VERSION ""

NS_ :

BS_:

BO_ 1120 NUM_TARGETS: 8 RADAR
  SG_ NUM_TARGETS : 20|5@0+ (1,0) [0|20] ""  NEO

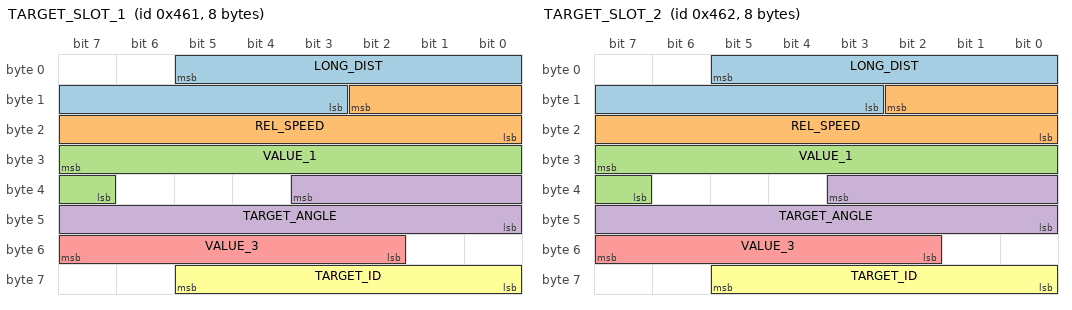
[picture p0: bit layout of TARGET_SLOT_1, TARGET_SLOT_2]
BO_ 1121 TARGET_SLOT_1: 8 RADAR
  SG_ LONG_DIST : 5|11@0+ (0.1,0) [0|200] "m"  NEO
  SG_ REL_SPEED : 10|11@0- (0.15,0) [0|122.85] "m/s"  NEO
  SG_ VALUE_1 : 31|9@0- (1,0) [0|1] ""  NEO
  SG_ TARGET_ANGLE : 35|12@0- (0.15,0) [-30|30] "deg"  NEO
  SG_ VALUE_3 : 55|6@0+ (1,0) [0|1] ""  NEO
  SG_ TARGET_ID : 61|6@0+ (1,0) [0|1] ""  NEO

BO_ 1122 TARGET_SLOT_2: 8 RADAR
  SG_ LONG_DIST : 5|11@0+ (0.1,0) [0|200] "m"  NEO
  SG_ REL_SPEED : 10|11@0- (0.15,0) [0|122.85] "m/s"  NEO
  SG_ VALUE_1 : 31|9@0- (1,0) [0|1] ""  NEO
  SG_ TARGET_ANGLE : 35|12@0- (0.15,0) [-30|30] "deg"  NEO
  SG_ VALUE_3 : 55|6@0+ (1,0) [0|1] ""  NEO
  SG_ TARGET_ID : 61|6@0+ (1,0) [0|1] ""  NEO

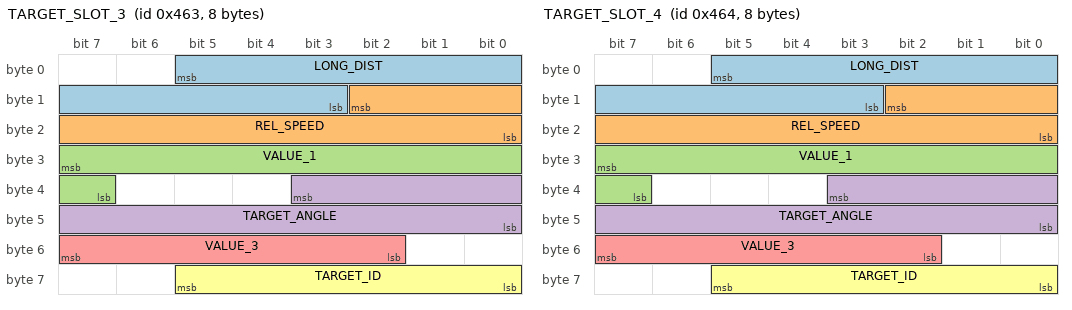
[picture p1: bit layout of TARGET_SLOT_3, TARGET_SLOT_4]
BO_ 1123 TARGET_SLOT_3: 8 RADAR
  SG_ LONG_DIST : 5|11@0+ (0.1,0) [0|200] "m"  NEO
  SG_ REL_SPEED : 10|11@0- (0.15,0) [0|122.85] "m/s"  NEO
  SG_ VALUE_1 : 31|9@0- (1,0) [0|1] ""  NEO
  SG_ TARGET_ANGLE : 35|12@0- (0.15,0) [-30|30] "deg"  NEO
  SG_ VALUE_3 : 55|6@0+ (1,0) [0|1] ""  NEO
  SG_ TARGET_ID : 61|6@0+ (1,0) [0|1] ""  NEO

BO_ 1124 TARGET_SLOT_4: 8 RADAR
  SG_ LONG_DIST : 5|11@0+ (0.1,0) [0|200] "m"  NEO
  SG_ REL_SPEED : 10|11@0- (0.15,0) [0|122.85] "m/s"  NEO
  SG_ VALUE_1 : 31|9@0- (1,0) [0|1] ""  NEO
  SG_ TARGET_ANGLE : 35|12@0- (0.15,0) [-30|30] "deg"  NEO
  SG_ VALUE_3 : 55|6@0+ (1,0) [0|1] ""  NEO
  SG_ TARGET_ID : 61|6@0+ (1,0) [0|1] ""  NEO

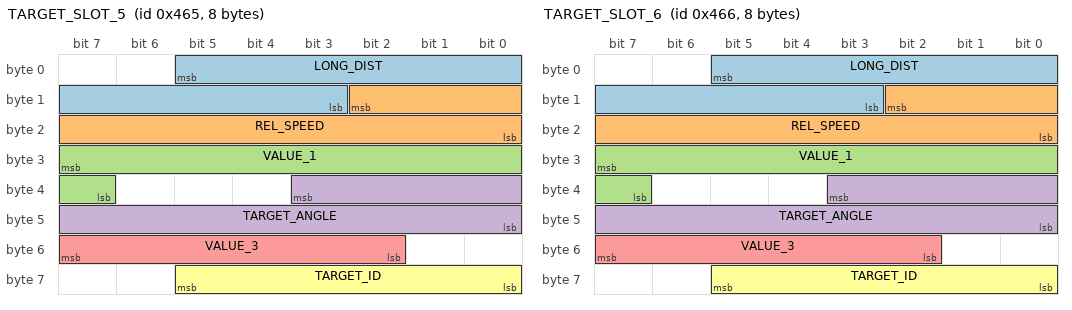
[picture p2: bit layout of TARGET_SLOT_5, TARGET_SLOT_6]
BO_ 1125 TARGET_SLOT_5: 8 RADAR
  SG_ LONG_DIST : 5|11@0+ (0.1,0) [0|200] "m"  NEO
  SG_ REL_SPEED : 10|11@0- (0.15,0) [0|122.85] "m/s"  NEO
  SG_ VALUE_1 : 31|9@0- (1,0) [0|1] ""  NEO
  SG_ TARGET_ANGLE : 35|12@0- (0.15,0) [-30|30] "deg"  NEO
  SG_ VALUE_3 : 55|6@0+ (1,0) [0|1] ""  NEO
  SG_ TARGET_ID : 61|6@0+ (1,0) [0|1] ""  NEO

BO_ 1126 TARGET_SLOT_6: 8 RADAR
  SG_ LONG_DIST : 5|11@0+ (0.1,0) [0|200] "m"  NEO
  SG_ REL_SPEED : 10|11@0- (0.15,0) [0|122.85] "m/s"  NEO
  SG_ VALUE_1 : 31|9@0- (1,0) [0|1] ""  NEO
  SG_ TARGET_ANGLE : 35|12@0- (0.15,0) [-30|30] "deg"  NEO
  SG_ VALUE_3 : 55|6@0+ (1,0) [0|1] ""  NEO
  SG_ TARGET_ID : 61|6@0+ (1,0) [0|1] ""  NEO

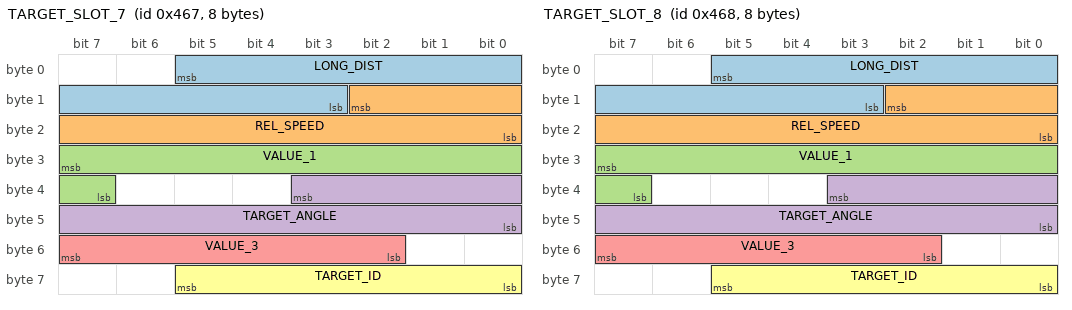
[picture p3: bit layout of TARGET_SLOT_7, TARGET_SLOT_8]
BO_ 1127 TARGET_SLOT_7: 8 RADAR
  SG_ LONG_DIST : 5|11@0+ (0.1,0) [0|200] "m"  NEO
  SG_ REL_SPEED : 10|11@0- (0.15,0) [0|122.85] "m/s"  NEO
  SG_ VALUE_1 : 31|9@0- (1,0) [0|1] ""  NEO
  SG_ TARGET_ANGLE : 35|12@0- (0.15,0) [-30|30] "deg"  NEO
  SG_ VALUE_3 : 55|6@0+ (1,0) [0|1] ""  NEO
  SG_ TARGET_ID : 61|6@0+ (1,0) [0|1] ""  NEO

BO_ 1128 TARGET_SLOT_8: 8 RADAR
  SG_ LONG_DIST : 5|11@0+ (0.1,0) [0|200] "m"  NEO
  SG_ REL_SPEED : 10|11@0- (0.15,0) [0|122.85] "m/s"  NEO
  SG_ VALUE_1 : 31|9@0- (1,0) [0|1] ""  NEO
  SG_ TARGET_ANGLE : 35|12@0- (0.15,0) [-30|30] "deg"  NEO
  SG_ VALUE_3 : 55|6@0+ (1,0) [0|1] ""  NEO
  SG_ TARGET_ID : 61|6@0+ (1,0) [0|1] ""  NEO

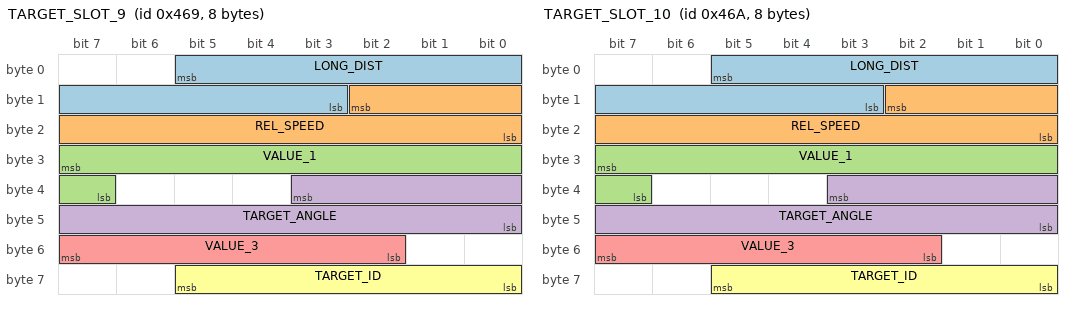
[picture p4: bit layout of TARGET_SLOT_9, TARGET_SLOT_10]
BO_ 1129 TARGET_SLOT_9: 8 RADAR
  SG_ LONG_DIST : 5|11@0+ (0.1,0) [0|200] "m"  NEO
  SG_ REL_SPEED : 10|11@0- (0.15,0) [0|122.85] "m/s"  NEO
  SG_ VALUE_1 : 31|9@0- (1,0) [0|1] ""  NEO
  SG_ TARGET_ANGLE : 35|12@0- (0.15,0) [-30|30] "deg"  NEO
  SG_ VALUE_3 : 55|6@0+ (1,0) [0|1] ""  NEO
  SG_ TARGET_ID : 61|6@0+ (1,0) [0|1] ""  NEO

BO_ 1130 TARGET_SLOT_10: 8 RADAR
  SG_ LONG_DIST : 5|11@0+ (0.1,0) [0|200] "m"  NEO
  SG_ REL_SPEED : 10|11@0- (0.15,0) [0|122.85] "m/s"  NEO
  SG_ VALUE_1 : 31|9@0- (1,0) [0|1] ""  NEO
  SG_ TARGET_ANGLE : 35|12@0- (0.15,0) [-30|30] "deg"  NEO
  SG_ VALUE_3 : 55|6@0+ (1,0) [0|1] ""  NEO
  SG_ TARGET_ID : 61|6@0+ (1,0) [0|1] ""  NEO

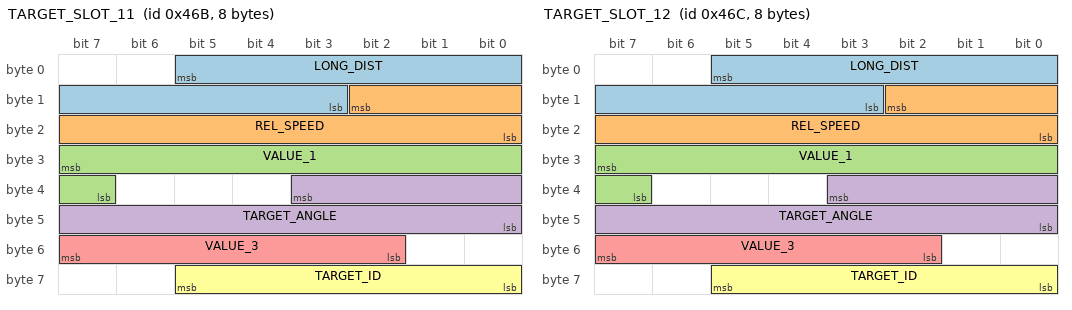
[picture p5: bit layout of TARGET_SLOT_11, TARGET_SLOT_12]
BO_ 1131 TARGET_SLOT_11: 8 RADAR
  SG_ LONG_DIST : 5|11@0+ (0.1,0) [0|200] "m"  NEO
  SG_ REL_SPEED : 10|11@0- (0.15,0) [0|122.85] "m/s"  NEO
  SG_ VALUE_1 : 31|9@0- (1,0) [0|1] ""  NEO
  SG_ TARGET_ANGLE : 35|12@0- (0.15,0) [-30|30] "deg"  NEO
  SG_ VALUE_3 : 55|6@0+ (1,0) [0|1] ""  NEO
  SG_ TARGET_ID : 61|6@0+ (1,0) [0|1] ""  NEO

BO_ 1132 TARGET_SLOT_12: 8 RADAR
  SG_ LONG_DIST : 5|11@0+ (0.1,0) [0|200] "m"  NEO
  SG_ REL_SPEED : 10|11@0- (0.15,0) [0|122.85] "m/s"  NEO
  SG_ VALUE_1 : 31|9@0- (1,0) [0|1] ""  NEO
  SG_ TARGET_ANGLE : 35|12@0- (0.15,0) [-30|30] "deg"  NEO
  SG_ VALUE_3 : 55|6@0+ (1,0) [0|1] ""  NEO
  SG_ TARGET_ID : 61|6@0+ (1,0) [0|1] ""  NEO

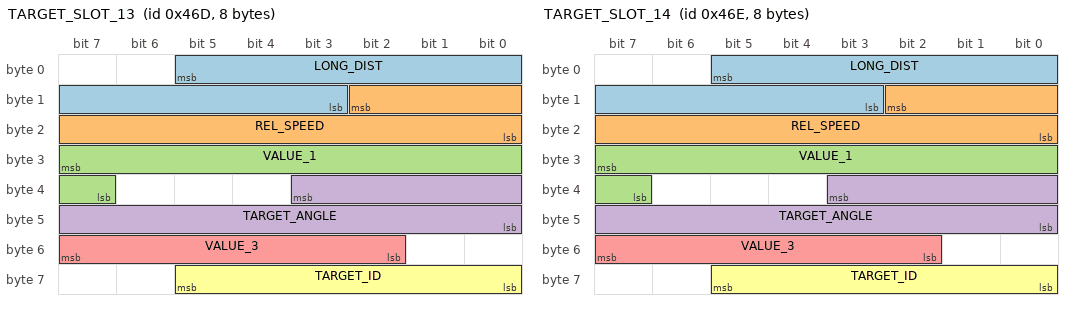
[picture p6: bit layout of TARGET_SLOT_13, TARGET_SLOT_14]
BO_ 1133 TARGET_SLOT_13: 8 RADAR
  SG_ LONG_DIST : 5|11@0+ (0.1,0) [0|200] "m"  NEO
  SG_ REL_SPEED : 10|11@0- (0.15,0) [0|122.85] "m/s"  NEO
  SG_ VALUE_1 : 31|9@0- (1,0) [0|1] ""  NEO
  SG_ TARGET_ANGLE : 35|12@0- (0.15,0) [-30|30] "deg"  NEO
  SG_ VALUE_3 : 55|6@0+ (1,0) [0|1] ""  NEO
  SG_ TARGET_ID : 61|6@0+ (1,0) [0|1] ""  NEO

BO_ 1134 TARGET_SLOT_14: 8 RADAR
  SG_ LONG_DIST : 5|11@0+ (0.1,0) [0|200] "m"  NEO
  SG_ REL_SPEED : 10|11@0- (0.15,0) [0|122.85] "m/s"  NEO
  SG_ VALUE_1 : 31|9@0- (1,0) [0|1] ""  NEO
  SG_ TARGET_ANGLE : 35|12@0- (0.15,0) [-30|30] "deg"  NEO
  SG_ VALUE_3 : 55|6@0+ (1,0) [0|1] ""  NEO
  SG_ TARGET_ID : 61|6@0+ (1,0) [0|1] ""  NEO

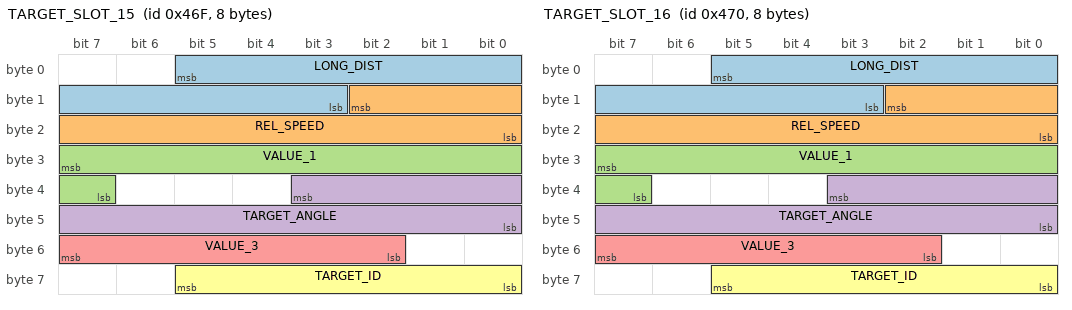
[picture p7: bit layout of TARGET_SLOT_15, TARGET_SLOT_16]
BO_ 1135 TARGET_SLOT_15: 8 RADAR
  SG_ LONG_DIST : 5|11@0+ (0.1,0) [0|200] "m"  NEO
  SG_ REL_SPEED : 10|11@0- (0.15,0) [0|122.85] "m/s"  NEO
  SG_ VALUE_1 : 31|9@0- (1,0) [0|1] ""  NEO
  SG_ TARGET_ANGLE : 35|12@0- (0.15,0) [-30|30] "deg"  NEO
  SG_ VALUE_3 : 55|6@0+ (1,0) [0|1] ""  NEO
  SG_ TARGET_ID : 61|6@0+ (1,0) [0|1] ""  NEO

BO_ 1136 TARGET_SLOT_16: 8 RADAR
  SG_ LONG_DIST : 5|11@0+ (0.1,0) [0|200] "m"  NEO
  SG_ REL_SPEED : 10|11@0- (0.15,0) [0|122.85] "m/s"  NEO
  SG_ VALUE_1 : 31|9@0- (1,0) [0|1] ""  NEO
  SG_ TARGET_ANGLE : 35|12@0- (0.15,0) [-30|30] "deg"  NEO
  SG_ VALUE_3 : 55|6@0+ (1,0) [0|1] ""  NEO
  SG_ TARGET_ID : 61|6@0+ (1,0) [0|1] ""  NEO

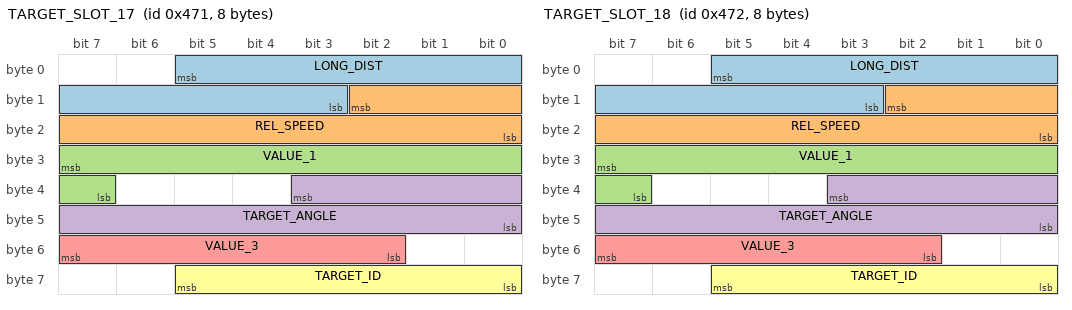
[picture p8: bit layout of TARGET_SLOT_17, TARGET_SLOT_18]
BO_ 1137 TARGET_SLOT_17: 8 RADAR
  SG_ LONG_DIST : 5|11@0+ (0.1,0) [0|200] "m"  NEO
  SG_ REL_SPEED : 10|11@0- (0.15,0) [0|122.85] "m/s"  NEO
  SG_ VALUE_1 : 31|9@0- (1,0) [0|1] ""  NEO
  SG_ TARGET_ANGLE : 35|12@0- (0.15,0) [-30|30] "deg"  NEO
  SG_ VALUE_3 : 55|6@0+ (1,0) [0|1] ""  NEO
  SG_ TARGET_ID : 61|6@0+ (1,0) [0|1] ""  NEO

BO_ 1138 TARGET_SLOT_18: 8 RADAR
  SG_ LONG_DIST : 5|11@0+ (0.1,0) [0|200] "m"  NEO
  SG_ REL_SPEED : 10|11@0- (0.15,0) [0|122.85] "m/s"  NEO
  SG_ VALUE_1 : 31|9@0- (1,0) [0|1] ""  NEO
  SG_ TARGET_ANGLE : 35|12@0- (0.15,0) [-30|30] "deg"  NEO
  SG_ VALUE_3 : 55|6@0+ (1,0) [0|1] ""  NEO
  SG_ TARGET_ID : 61|6@0+ (1,0) [0|1] ""  NEO

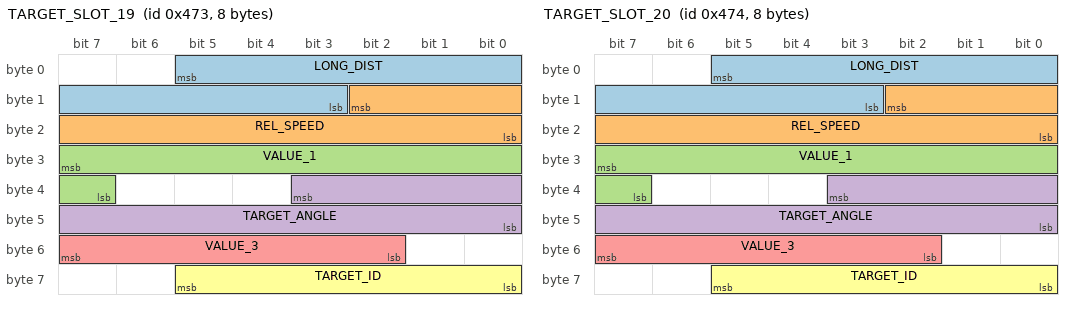
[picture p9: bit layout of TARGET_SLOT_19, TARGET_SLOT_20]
BO_ 1139 TARGET_SLOT_19: 8 RADAR
  SG_ LONG_DIST : 5|11@0+ (0.1,0) [0|200] "m"  NEO
  SG_ REL_SPEED : 10|11@0- (0.15,0) [0|122.85] "m/s"  NEO
  SG_ VALUE_1 : 31|9@0- (1,0) [0|1] ""  NEO
  SG_ TARGET_ANGLE : 35|12@0- (0.15,0) [-30|30] "deg"  NEO
  SG_ VALUE_3 : 55|6@0+ (1,0) [0|1] ""  NEO
  SG_ TARGET_ID : 61|6@0+ (1,0) [0|1] ""  NEO

BO_ 1140 TARGET_SLOT_20: 8 RADAR
  SG_ LONG_DIST : 5|11@0+ (0.1,0) [0|200] "m"  NEO
  SG_ REL_SPEED : 10|11@0- (0.15,0) [0|122.85] "m/s"  NEO
  SG_ VALUE_1 : 31|9@0- (1,0) [0|1] ""  NEO
  SG_ TARGET_ANGLE : 35|12@0- (0.15,0) [-30|30] "deg"  NEO
  SG_ VALUE_3 : 55|6@0+ (1,0) [0|1] ""  NEO
  SG_ TARGET_ID : 61|6@0+ (1,0) [0|1] ""  NEO
